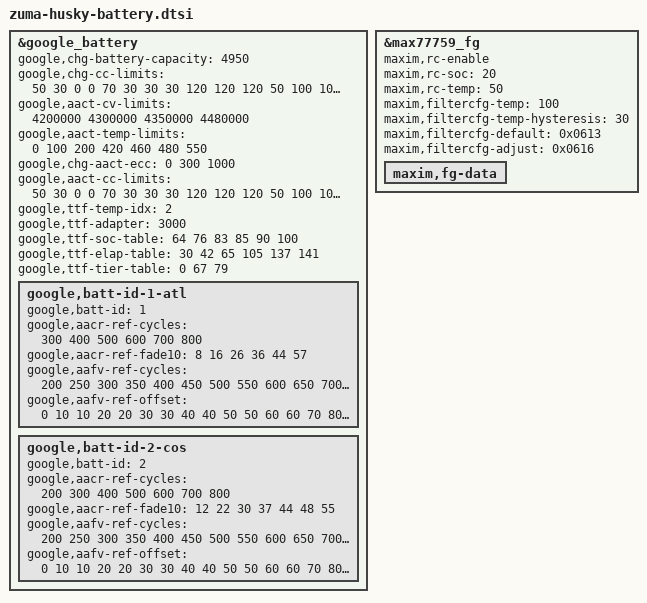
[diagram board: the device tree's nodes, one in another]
// SPDX-License-Identifier: GPL-2.0-only
/*
 * Battery device tree entries specific to panther
 *
 * Copyright 2022 Google,LLC
 *
 */

&google_battery {
	google,chg-battery-capacity = <4950>;
	google,chg-cc-limits = <
               50   30    0   0
               70   30   30  30
              120  120  120  50
              100  100  100  50
               50   50    0   0
               30    0    0   0
	>;

	google,aact-cv-limits = <4200000 4300000 4350000 4480000>;
	google,aact-temp-limits = <0 100 200 420 460 480 550>;
	google,chg-aact-ecc = <0 300 1000>;
	google,aact-cc-limits = <
               50   30    0   0
               70   30   30  30
              120  120  120  50
              100  100  100  50
               50   50    0   0
               30    0    0   0
               50   30    0   0
               70   30   30  30
              110  110  110  50
              100  100  100  50
               50   50    0   0
               30    0    0   0
               50   30    0   0
               70   30   30  30
              100  100  100  50
              100  100  100  50
               50   50    0   0
               30    0    0   0
	>;

	google,ttf-temp-idx= <2>;
	google,ttf-adapter = <3000>;
	google,ttf-soc-table =  <64 76 83 85  90  100>;
	google,ttf-elap-table = <30 42 65 105 137 141>;
	google,ttf-tier-table = <0 67 79>;

	google,batt-id-1-atl {
		google,batt-id = <1>;
		google,aacr-ref-cycles = <300 400 500 600 700 800>;
		google,aacr-ref-fade10 = <  8  16  26  36  44  57>;
		google,aafv-ref-cycles = <
			200  250  300  350  400  450  500  550
			600  650  700  750  800  850  900  950
		>;
		google,aafv-ref-offset = <
			  0  10  10  20  20  30  30  40
			 40  50  50  60  60  70  80  90
		>;
	};

	google,batt-id-2-cos {
		google,batt-id = <2>;
		google,aacr-ref-cycles = <200 300 400 500 600 700 800>;
		google,aacr-ref-fade10 = < 12  22  30  37  44  48  55>;
		google,aafv-ref-cycles = <
			200  250  300  350  400  450  500  550
			600  650  700  750  800  850  900  950
		>;
		google,aafv-ref-offset = <
			  0  10  10  20  20  30  30  40
			 40  50  50  60  60  70  80  90
		>;
	};
};

&max77759_fg {
	maxim,rc-enable;
	maxim,rc-soc = <20>;
	maxim,rc-temp = <50>;

	maxim,filtercfg-temp = <100>;
	maxim,filtercfg-temp-hysteresis = <30>;
	maxim,filtercfg-default = /bits/ 16 <0x0613>;
	maxim,filtercfg-adjust = /bits/ 16 <0x0616>;

	maxim,fg-data {
		#include "zuma-husky-battery-data.dtsi"
	};
};
